# M3U6 register map
File version: 2.0.2.11
Registers are 32-bit, read-write, reset 0x0 unless marked. A register's access mark holds for its fields unless they carry their own. Offsets are from the block's base; [hi:lo] are bit positions; {n}, {i} and the like mark numbered series.

## WD — Watchdog Timer (WD)
Base 0x40040000
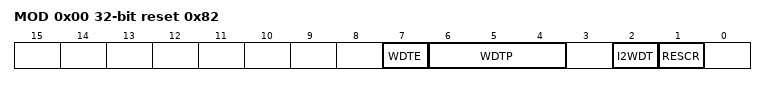
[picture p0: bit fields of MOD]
0x00 MOD reset 0x82 — WD Mode Register
  [7] WDTE, [6:4] WDTP, [2] I2WDT, [1] RESCR
0x04 CR wo (reset mask 0xFFFFFF00) — WD Control Register
  [7:0] WDCR

## RTC — Real Time Clock (RTC)
Base 0x40040100
0x00 SECR 8-bit (reset mask 0x80) — RTC Second Column Register
  [6:0] SE
0x01 MINR 8-bit (reset mask 0x80) — RTC Minute Column Register
  [6:0] MI
0x02 HOURR 8-bit (reset mask 0xC0) — RTC Hour Column Register
  [5:0] HO
0x04 DAYR 8-bit (reset mask 0xF8) — RTC Day of the Week Column Register
  [2:0] WE
0x05 DATER 8-bit (reset mask 0xC0) — RTC Day Column Register
  [5:0] DA
0x06 MONTHR_A 8-bit (reset mask 0xE0) — RTC Month Column Register
  [4:0] MO
0x06 MONTHR_B 8-bit (reset mask 0xFE) (RTC_MONTHR view) — RTC Month Column Register
  [0] MO0
0x07 YEARR_A 8-bit reset not defined — RTC Year Column Register
  [7:0] YE
0x07 YEARR_B 8-bit (reset mask 0xFC) (RTC_YEARR view) — RTC Year Column Register
  [1:0] LEAP
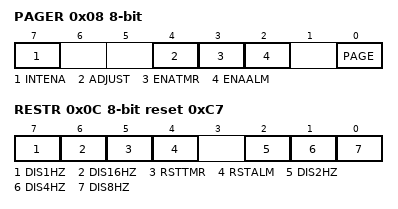
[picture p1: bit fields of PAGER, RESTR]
0x08 PAGER 8-bit (reset mask 0xF3) — RTC PAGE Register
  [7] INTENA, [4] ADJUST, [3] ENATMR, [2] ENAALM, [0] PAGE
0x0C RESTR 8-bit reset 0xC7 — RTC Reset Register
  [7] DIS1HZ, [6] DIS16HZ, [5] RSTTMR, [4] RSTALM, [2] DIS2HZ, [1] DIS4HZ, [0] DIS8HZ

## CG — Clock Generator (CG)
Base 0x40040200
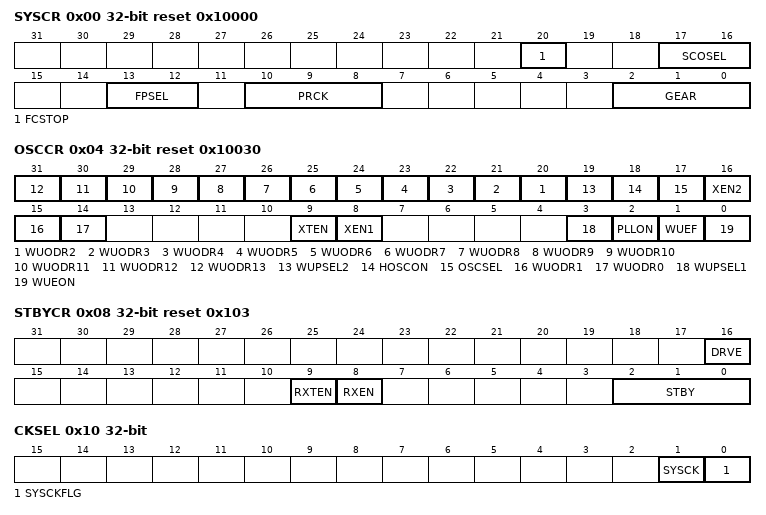
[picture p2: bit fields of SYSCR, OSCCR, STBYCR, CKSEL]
0x00 SYSCR reset 0x10000 — System Control Register
  [20] FCSTOP, [17:16] SCOSEL, [13:12] FPSEL, [10:8] PRCK, [2:0] GEAR
0x04 OSCCR reset 0x10030 — Oscillation Control Register
  [n+18] WUODR{n} (n=2..13), [19] WUPSEL2, [18] HOSCON, [17] OSCSEL, [16] XEN2, [15] WUODR1, [14] WUODR0, [9] XTEN, [8] XEN1, [3] WUPSEL1, [2] PLLON, [1] WUEF ro, [0] WUEON wo
0x08 STBYCR reset 0x103 — Standby Control Register
  [16] DRVE, [9] RXTEN, [8] RXEN, [2:0] STBY
0x0C PLLSEL reset 0x721E — PLL Selection Register
  [0] PLLSEL
0x10 CKSEL — System Clock Selection Register
  [1] SYSCK, [0] SYSCKFLG ro
0x14 ICRCG wo — CG Interrupt Request Clear Register
  [4:0] ICRCG
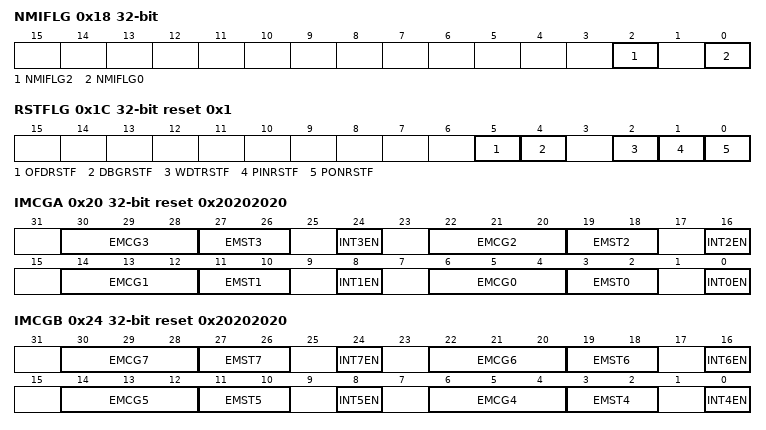
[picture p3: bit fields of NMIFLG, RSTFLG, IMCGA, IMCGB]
0x18 NMIFLG ro — NMI Flag Register
  [2] NMIFLG2, [0] NMIFLG0
0x1C RSTFLG reset 0x1 — Reset Flag Register
  [5] OFDRSTF, [4] DBGRSTF, [2] WDTRSTF, [1] PINRSTF, [0] PONRSTF
0x20 IMCGA reset 0x20202020 — CG Interrupt Mode Control Register A
  [8n+6:8n+4] EMCG{n} (n=0..3), [8n+3:8n+2] EMST{n} ro (n=0..3), [8n] INT{n}EN (n=0..3)
0x24 IMCGB reset 0x20202020 — CG Interrupt Mode Control Register B
  [8n-26:8n-28] EMCG{n} (n=4..7), [8n-29:8n-30] EMST{n} ro (n=4..7), [8n-32] INT{n}EN (n=4..7)
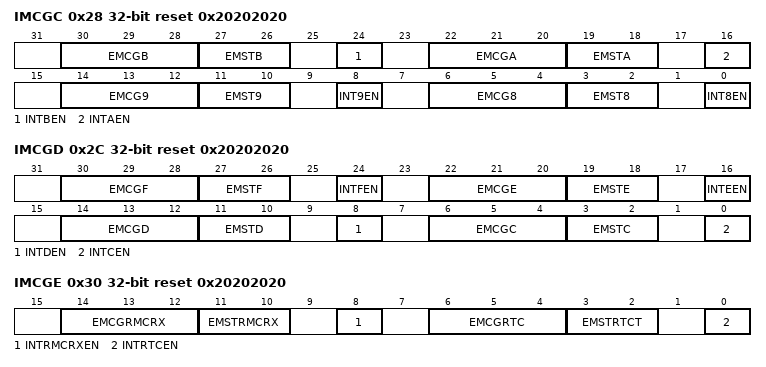
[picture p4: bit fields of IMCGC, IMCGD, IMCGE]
0x28 IMCGC reset 0x20202020 — CG Interrupt Mode Control Register C
  [30:28] EMCGB, [27:26] EMSTB ro, [24] INTBEN, [22:20] EMCGA, [19:18] EMSTA ro, [16] INTAEN, [14:12] EMCG9, [11:10] EMST9 ro, [8] INT9EN, [6:4] EMCG8, [3:2] EMST8 ro, [0] INT8EN
0x2C IMCGD reset 0x20202020 — CG Interrupt Mode Control Register D
  [30:28] EMCGF, [27:26] EMSTF ro, [24] INTFEN, [22:20] EMCGE, [19:18] EMSTE ro, [16] INTEEN, [14:12] EMCGD, [11:10] EMSTD ro, [8] INTDEN, [6:4] EMCGC, [3:2] EMSTC ro, [0] INTCEN
0x30 IMCGE reset 0x20202020 — CG Interrupt Mode Control Register E
  [14:12] EMCGRMCRX, [11:10] EMSTRMCRX ro, [8] INTRMCRXEN, [6:4] EMCGRTC, [3:2] EMSTRTCT ro, [0] INTRTCEN

## RMC — Remote Control Signal Preprocessor (RMC)
Base 0x40040400
0x00 EN — RMC Enable Register
  [0] RMCEN
0x04 REN — RMC Receive Enable Register
  [0] RMCREN
0x08 RBUF1 ro — RMC Receive Data Buffer Register 1
  [31:0] RMCRBUF
0x0C RBUF2 ro — RMC Receive Data Buffer Register 2
  [31:0] RMCRBUF
0x10 RBUF3 ro — RMC Receive Data Buffer Register 3
  [7:0] RMCRBUF
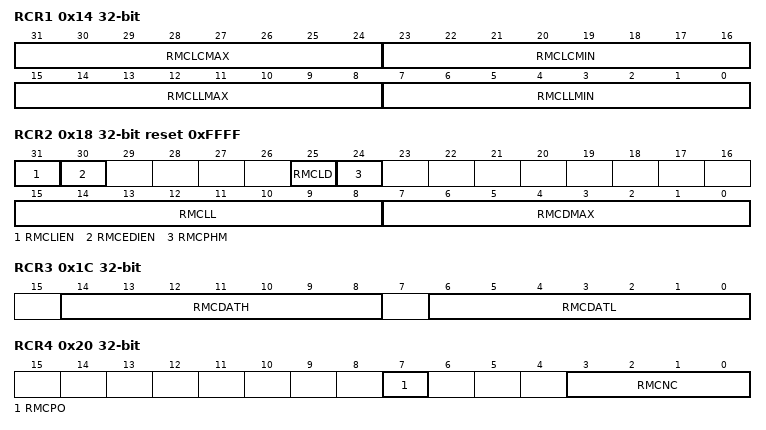
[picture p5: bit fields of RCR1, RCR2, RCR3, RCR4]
0x14 RCR1 — RMC Receive Control Register 1
  [31:24] RMCLCMAX, [23:16] RMCLCMIN, [15:8] RMCLLMAX, [7:0] RMCLLMIN
0x18 RCR2 reset 0xFFFF — RMC Receive Control Register 2
  [31] RMCLIEN, [30] RMCEDIEN, [25] RMCLD, [24] RMCPHM, [15:8] RMCLL, [7:0] RMCDMAX
0x1C RCR3 — RMC Receive Control Register 3
  [14:8] RMCDATH, [6:0] RMCDATL
0x20 RCR4 — RMC Receive Control Register 4
  [7] RMCPO, [3:0] RMCNC
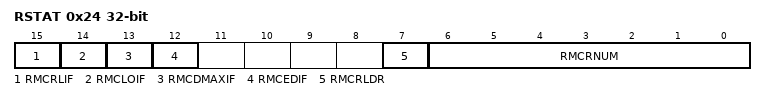
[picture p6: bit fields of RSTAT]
0x24 RSTAT ro — RMC Receive Status Register
  [15] RMCRLIF, [14] RMCLOIF, [13] RMCDMAXIF, [12] RMCEDIF, [7] RMCRLDR, [6:0] RMCRNUM
{0x24+4i} END{i} (i=1..3) — RMC Receive End Bit Number Register {i}
  [6:0] RMCEND{i}
0x34 FSSEL — RMC Frequency Selection Register
  [0] RMCCLK
